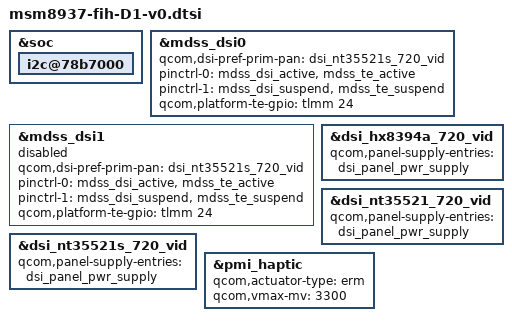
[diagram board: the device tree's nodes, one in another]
/*
 * Copyright (c) 2016, The Linux Foundation. All rights reserved.
 *
 * This program is free software; you can redistribute it and/or modify
 * it under the terms of the GNU General Public License version 2 and
 * only version 2 as published by the Free Software Foundation.
 *
 * This program is distributed in the hope that it will be useful,
 * but WITHOUT ANY WARRANTY; without even the implied warranty of
 * MERCHANTABILITY or FITNESS FOR A PARTICULAR PURPOSE.  See the
 * GNU General Public License for more details.
 */

#include "msm8937-pinctrl-ND1.dtsi"

#include "components/camera/msm8940-camera-sensor-d1_evb.dtsi"

&soc {

  /*  Add for external LDO control */
  /include/ "components/ext-reguator/fixed-regulator-D1-EVB-v1.dtsi"
  /include/ "components/hallsensor/hallsensor_v0.dtsi"
	i2c@78b7000 {
	  status = "ok";
	  /delete-node/ ili2121x@41;
	  #include "components/touch/touch_synaptics_i2c_0x20_v0.dtsi"
	};
};

&mdss_dsi0 {
	qcom,dsi-pref-prim-pan = <&dsi_nt35521s_720_vid>;
	pinctrl-names = "mdss_default", "mdss_sleep";
	pinctrl-0 = <&mdss_dsi_active &mdss_te_active>;
	pinctrl-1 = <&mdss_dsi_suspend &mdss_te_suspend>;

	qcom,platform-te-gpio = <&tlmm 24 0>;
};

&mdss_dsi1 {
	status = "disabled";
	qcom,dsi-pref-prim-pan = <&dsi_nt35521s_720_vid>;
	pinctrl-names = "mdss_default", "mdss_sleep";
	pinctrl-0 = <&mdss_dsi_active &mdss_te_active>;
	pinctrl-1 = <&mdss_dsi_suspend &mdss_te_suspend>;

	qcom,platform-te-gpio = <&tlmm 24 0>;
};

&dsi_hx8394a_720_vid {
	qcom,panel-supply-entries = <&dsi_panel_pwr_supply>;
};

&dsi_nt35521_720_vid {
	qcom,panel-supply-entries = <&dsi_panel_pwr_supply>;
};

&dsi_nt35521s_720_vid {
	qcom,panel-supply-entries = <&dsi_panel_pwr_supply>;
};

&pmi_haptic{
	qcom,actuator-type = "erm";
	qcom,vmax-mv = <3300>;
};
